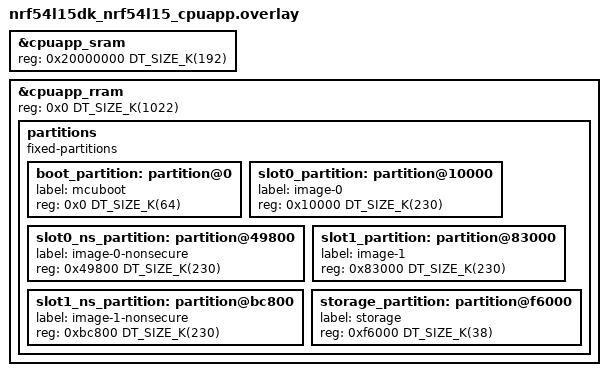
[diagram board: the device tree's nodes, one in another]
/*
 * Copyright (c) 2024 Nordic Semiconductor
 * SPDX-License-Identifier: LicenseRef-Nordic-5-Clause
 */

&cpuapp_sram {
	reg = <0x20000000 DT_SIZE_K(192)>;
	ranges = <0x0 0x20000000 DT_SIZE_K(192)>;
};

&cpuapp_rram {
	reg = <0x0 DT_SIZE_K(1022)>;
};

/delete-node/ &boot_partition;
/delete-node/ &slot0_partition;
/delete-node/ &slot0_ns_partition;
/delete-node/ &slot1_partition;
/delete-node/ &slot1_ns_partition;
/delete-node/ &storage_partition;

&cpuapp_rram {
	partitions {
		compatible = "fixed-partitions";
		#address-cells = <1>;
		#size-cells = <1>;
		boot_partition: partition@0 {
			label = "mcuboot";
			reg = <0x0 DT_SIZE_K(64)>;
		};
		slot0_partition: partition@10000 {
			label = "image-0";
			reg = <0x10000 DT_SIZE_K(230)>;
		};
		slot0_ns_partition: partition@49800 {
			label = "image-0-nonsecure";
			reg = <0x49800 DT_SIZE_K(230)>;
		};
		slot1_partition: partition@83000 {
			label = "image-1";
			reg = <0x83000 DT_SIZE_K(230)>;
		};
		slot1_ns_partition: partition@bc800 {
			label = "image-1-nonsecure";
			reg = <0xbc800 DT_SIZE_K(230)>;
		};
		storage_partition: partition@f6000 {
			label = "storage";
			reg = <0xf6000 DT_SIZE_K(38)>;
		};
	};
};
